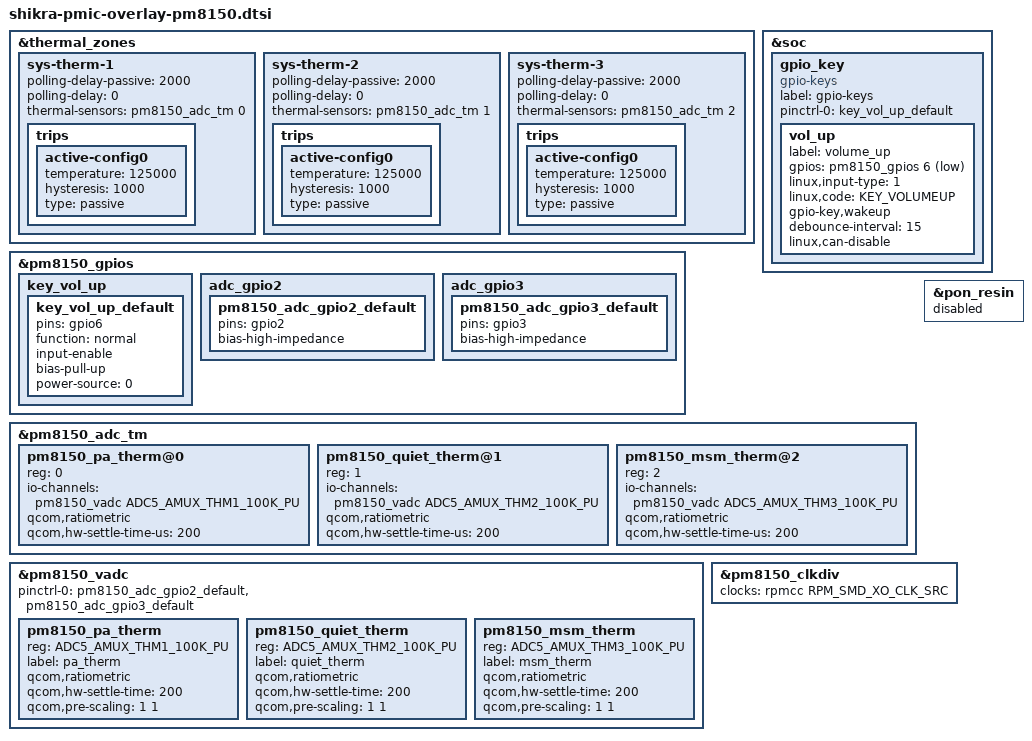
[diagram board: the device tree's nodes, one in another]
// SPDX-License-Identifier: BSD-3-Clause
/*
 * Copyright (c) Qualcomm Technologies, Inc. and/or its subsidiaries.
 */

#include <dt-bindings/gpio/gpio.h>
#include <dt-bindings/input/input.h>
#include <dt-bindings/iio/qcom,spmi-vadc.h>

#include "pm8150.dtsi"

&thermal_zones {
	sys-therm-1 {
		polling-delay-passive = <2000>;
		polling-delay = <0>;
		thermal-sensors = <&pm8150_adc_tm 0>;

		trips {
			active-config0 {
				temperature = <125000>;
				hysteresis = <1000>;
				type = "passive";
			};
		};
	};

	sys-therm-2 {
		polling-delay-passive = <2000>;
		polling-delay = <0>;
		thermal-sensors = <&pm8150_adc_tm 1>;

		trips {
			active-config0 {
				temperature = <125000>;
				hysteresis = <1000>;
				type = "passive";
			};
		};
	};

	sys-therm-3 {
		polling-delay-passive = <2000>;
		polling-delay = <0>;
		thermal-sensors = <&pm8150_adc_tm 2>;

		trips {
			active-config0 {
				temperature = <125000>;
				hysteresis = <1000>;
				type = "passive";
			};
		};
	};
};

&pm8150_gpios {
	key_vol_up {
		key_vol_up_default: key_vol_up_default {
			pins = "gpio6";
			function = "normal";
			input-enable;
			bias-pull-up;
			power-source = <0>;
		};
	};

	adc_gpio2 {
		pm8150_adc_gpio2_default: pm8150_adc_gpio2_default {
			pins = "gpio2";
			bias-high-impedance;
		};
	};

	adc_gpio3 {
		pm8150_adc_gpio3_default: pm8150_adc_gpio3_default {
			pins = "gpio3";
			bias-high-impedance;
		};
	};
};

&soc {

	gpio_key {
		compatible = "gpio-keys";
		label = "gpio-keys";
		pinctrl-names = "default";
		pinctrl-0 = <&key_vol_up_default>;

		vol_up {
			label = "volume_up";
			gpios = <&pm8150_gpios 6 GPIO_ACTIVE_LOW>;
			linux,input-type = <1>;
			linux,code = <KEY_VOLUMEUP>;
			gpio-key,wakeup;
			debounce-interval = <15>;
			linux,can-disable;
		};
	};

};

&pm8150_adc_tm {
	pm8150_pa_therm@0 {
		reg = <0>;
		io-channels = <&pm8150_vadc ADC5_AMUX_THM1_100K_PU>;
		qcom,ratiometric;
		qcom,hw-settle-time-us = <200>;
	};

	pm8150_quiet_therm@1 {
		reg = <1>;
		io-channels = <&pm8150_vadc ADC5_AMUX_THM2_100K_PU>;
		qcom,ratiometric;
		qcom,hw-settle-time-us = <200>;
	};

	pm8150_msm_therm@2 {
		reg = <2>;
		io-channels = <&pm8150_vadc ADC5_AMUX_THM3_100K_PU>;
		qcom,ratiometric;
		qcom,hw-settle-time-us = <200>;
	};
};

&pm8150_vadc {
	pinctrl-0 = <&pm8150_adc_gpio2_default>, <&pm8150_adc_gpio3_default>;
	pinctrl-names = "default";

	pm8150_pa_therm {
		reg = <ADC5_AMUX_THM1_100K_PU>;
		label = "pa_therm";
		qcom,ratiometric;
		qcom,hw-settle-time = <200>;
		qcom,pre-scaling = <1 1>;
	};

	pm8150_quiet_therm {
		reg = <ADC5_AMUX_THM2_100K_PU>;
		label = "quiet_therm";
		qcom,ratiometric;
		qcom,hw-settle-time = <200>;
		qcom,pre-scaling = <1 1>;
	};

	pm8150_msm_therm {
		reg = <ADC5_AMUX_THM3_100K_PU>;
		label = "msm_therm";
		qcom,ratiometric;
		qcom,hw-settle-time = <200>;
		qcom,pre-scaling = <1 1>;
	};
};

&pon_resin {
	status = "disabled";
};

&pm8150_clkdiv {
	clocks = <&rpmcc RPM_SMD_XO_CLK_SRC>;
};
